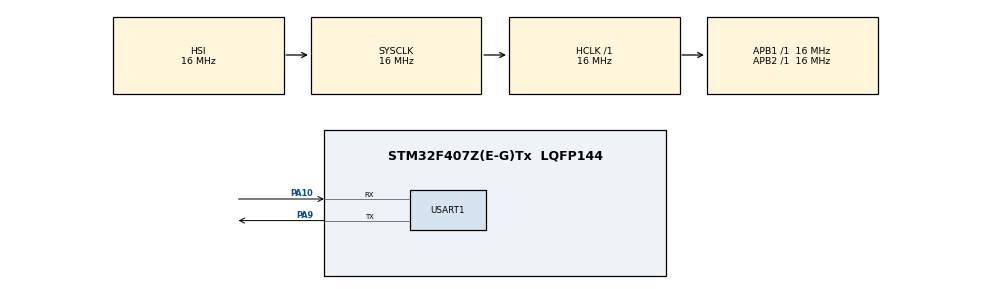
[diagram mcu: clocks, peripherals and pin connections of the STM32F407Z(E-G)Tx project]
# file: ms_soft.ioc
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Mcu.Family=STM32F4
Mcu.Name=STM32F407Z(E-G)Tx
Mcu.Package=LQFP144
NVIC.PriorityGroup=NVIC_PRIORITYGROUP_4
PA10.Mode=Asynchronous
PA10.Signal=USART1_RX
PA13.Mode=Serial_Wire
PA13.Signal=SYS_JTMS-SWDIO
PA14.Mode=Serial_Wire
PA14.Signal=SYS_JTCK-SWCLK
PA9.Mode=Asynchronous
PA9.Signal=USART1_TX
PH0-OSC_IN.Mode=HSE-External-Oscillator
PH0-OSC_IN.Signal=RCC_OSC_IN
PH1-OSC_OUT.Mode=HSE-External-Oscillator
PH1-OSC_OUT.Signal=RCC_OSC_OUT
ProjectManager.HeapSize=0x200
ProjectManager.StackSize=0x400
ProjectManager.TargetToolchain=CMake
RCC.AHBFreq_Value=16000000
RCC.APB1Freq_Value=16000000
RCC.APB2Freq_Value=16000000
RCC.CortexFreq_Value=16000000
RCC.HSE_VALUE=25000000
RCC.HSI_VALUE=16000000
RCC.LSE_VALUE=32768
RCC.SYSCLKFreq_VALUE=16000000
RCC.VCOOutputFreq_Value=192000000
USART1.VirtualMode=VM_ASYNC
board=custom

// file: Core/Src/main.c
/* USER CODE BEGIN Header */
/**
  ******************************************************************************
  * @file           : main.c
  * @brief          : Main program body
  ******************************************************************************
  * @attention
  *
  * Copyright (c) 2026 STMicroelectronics.
  * All rights reserved.
  *
  * This software is licensed under terms that can be found in the LICENSE file
  * in the root directory of this software component.
  * If no LICENSE file comes with this software, it is provided AS-IS.
  *
  ******************************************************************************
  */
/* USER CODE END Header */
#include "main.h"
#include "usart.h"
#include "gpio.h"

/* USER CODE BEGIN Includes */
#include "ms5837.h"
#include <stdio.h>     // sprintf
/* USER CODE END Includes */

/* USER CODE BEGIN PV */
uint32_t lastTick = 0;  // 上一次发送的 tick
/* USER CODE END PV */

void SystemClock_Config(void);

int main(void)
{

  /* MCU Configuration--------------------------------------------------------*/

  /* Reset of all peripherals, Initializes the Flash interface and the Systick. */
  HAL_Init();

  /* Configure the system clock */
  SystemClock_Config();

  /* Initialize all configured peripherals */
  MX_GPIO_Init();
  MX_USART1_UART_Init();
  /* USER CODE BEGIN 2 */
  Soft_I2C_Init();

  MS5837_StatusTypeDef st = MS5837_init();
  char init_msg[64];
  int init_len = sprintf(init_msg, "MS5837 init=%d, P=%d mbar\r\n",
                         (int)st, (int)Atmdsphere_Pressure);
  HAL_UART_Transmit(&huart1, (uint8_t *)init_msg, init_len, HAL_MAX_DELAY);
  /* USER CODE END 2 */

  /* Infinite loop */
  /* USER CODE BEGIN WHILE */
  while (1)
  {
	  MS5837_Getdata();
	  if (HAL_GetTick() - lastTick >= 1000)   // 距上次发送满 1 秒
	  {
	      lastTick = HAL_GetTick();

	      /* 手动拆分 Depth 的整数/小数，避开 newlib-nano 打不了 %f 的坑 */
	      float d = Depth;
	      if (d < 0.0f) d = 0.0f;
	      int depth_i = (int)d;
	      int depth_f = (int)((d - depth_i) * 10.0f);

	      int p_i = (int)Pressure;
	      int p_f = (int)((Pressure - p_i) * 10.0f);

	      char buf[64];
	      int len = sprintf(buf, "P=%d.%d mbar  Depth=%d.%d cm\r\n",
	                        p_i, p_f, depth_i, depth_f);
	      HAL_UART_Transmit(&huart1, (uint8_t *)buf, len, HAL_MAX_DELAY);
	  }
	  HAL_Delay(100);
    /* USER CODE END WHILE */

  }
}

void SystemClock_Config(void)
{
  RCC_OscInitTypeDef RCC_OscInitStruct = {0};
  RCC_ClkInitTypeDef RCC_ClkInitStruct = {0};

  /** Configure the main internal regulator output voltage
  */
  __HAL_RCC_PWR_CLK_ENABLE();
  __HAL_PWR_VOLTAGESCALING_CONFIG(PWR_REGULATOR_VOLTAGE_SCALE1);

  /** Initializes the RCC Oscillators according to the specified parameters
  * in the RCC_OscInitTypeDef structure.
  */
  RCC_OscInitStruct.OscillatorType = RCC_OSCILLATORTYPE_HSI;
  RCC_OscInitStruct.HSIState = RCC_HSI_ON;
  RCC_OscInitStruct.HSICalibrationValue = RCC_HSICALIBRATION_DEFAULT;
  RCC_OscInitStruct.PLL.PLLState = RCC_PLL_NONE;
  if (HAL_RCC_OscConfig(&RCC_OscInitStruct) != HAL_OK)
  {
    Error_Handler();
  }

  /** Initializes the CPU, AHB and APB buses clocks
  */
  RCC_ClkInitStruct.ClockType = RCC_CLOCKTYPE_HCLK|RCC_CLOCKTYPE_SYSCLK
                              |RCC_CLOCKTYPE_PCLK1|RCC_CLOCKTYPE_PCLK2;
  RCC_ClkInitStruct.SYSCLKSource = RCC_SYSCLKSOURCE_HSI;
  RCC_ClkInitStruct.AHBCLKDivider = RCC_SYSCLK_DIV1;
  RCC_ClkInitStruct.APB1CLKDivider = RCC_HCLK_DIV1;
  RCC_ClkInitStruct.APB2CLKDivider = RCC_HCLK_DIV1;

  if (HAL_RCC_ClockConfig(&RCC_ClkInitStruct, FLASH_LATENCY_0) != HAL_OK)
  {
    Error_Handler();
  }
}

void Error_Handler(void)
{
  __disable_irq();
  while (1)
  {
  }
}
